# ATSAM3S2B device description
Architecture: CORTEX-M3; Family: SAM3; Series: SAM3S
Registers are 32-bit, read-write, no defined reset value unless marked. A register's access mark holds for its fields unless they carry their own. Offsets are from the block's base; [hi:lo] are bit positions; {n}, {i} and the like mark numbered series.

## CRCCU — Cyclic Redundancy Check Calculation Unit
Instances: CRCCU 0x40044000
0x00 CRCCU_DSCR — CRCCU Descriptor Base Register
  [31:9] DSCR — Descriptor Base Address
0x08 CRCCU_DMA_EN wo — CRCCU DMA Enable Register
  [0] DMAEN — DMA Enable Register
0x0C CRCCU_DMA_DIS wo — CRCCU DMA Disable Register
  [0] DMADIS — DMA Disable Register
0x10 CRCCU_DMA_SR ro — CRCCU DMA Status Register
  [0] DMASR — DMA Status Register
0x14 CRCCU_DMA_IER wo — CRCCU DMA Interrupt Enable Register
  [0] DMAIER — Interrupt Enable register
0x18 CRCCU_DMA_IDR wo — CRCCU DMA Interrupt Disable Register
  [0] DMAIDR — Interrupt Disable register
0x1C CRCCU_DMA_IMR ro — CRCCU DMA Interrupt Mask Register
  [0] DMAIMR — Interrupt Mask Register
0x20 CRCCU_DMA_ISR ro — CRCCU DMA Interrupt Status Register
  [0] DMAISR — Interrupt Status register
0x34 CRCCU_CR wo — CRCCU Control Register
  [0] RESET — CRC Computation Reset
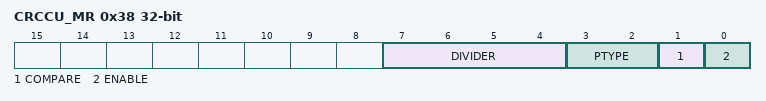
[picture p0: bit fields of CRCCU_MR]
0x38 CRCCU_MR — CRCCU Mode Register
  [7:4] DIVIDER — Request Divider
  [3:2] PTYPE — Primitive Polynomial
    0=CCITT8023 (Polynom 0x04C11DB7); 1=CASTAGNOLI (Polynom 0x1EDC6F41); 2=CCITT16 (Polynom 0x1021)
  [1] COMPARE — CRC Compare
  [0] ENABLE — CRC Enable
0x3C CRCCU_SR ro — CRCCU Status Register
  [31:0] CRC — Cyclic Redundancy Check Value
0x40 CRCCU_IER wo — CRCCU Interrupt Enable Register
  [0] ERRIER — CRC Error Interrupt Enable
0x44 CRCCU_IDR wo — CRCCU Interrupt Disable Register
  [0] ERRIDR — CRC Error Interrupt Disable
0x48 CRCCU_IMR ro — CRCCU Interrupt Mask Register
  [0] ERRIMR — CRC Error Interrupt Mask
0x4C CRCCU_ISR ro — CRCCU Interrupt Status Register
  [0] ERRISR — CRC Error Interrupt Status

## EFC — Embedded Flash Controller
Instances: EFC 0x400E0A00
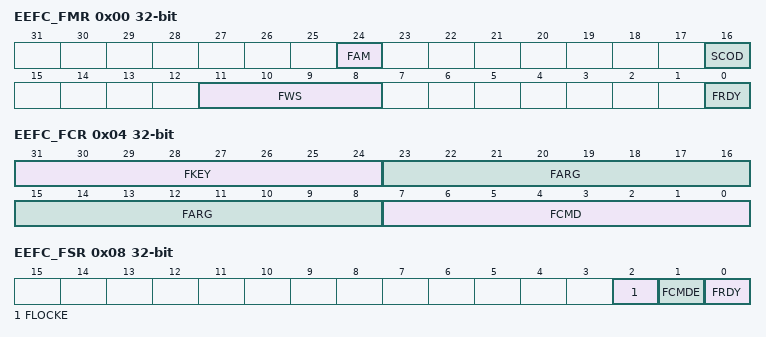
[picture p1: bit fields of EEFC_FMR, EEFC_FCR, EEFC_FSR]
0x00 EEFC_FMR — EEFC Flash Mode Register
  [24] FAM — Flash Access Mode
  [16] SCOD — Sequential Code Optimization Disable
  [11:8] FWS — Flash Wait State
  [0] FRDY — Ready Interrupt Enable
0x04 EEFC_FCR wo — EEFC Flash Command Register
  [31:24] FKEY — Flash Writing Protection Key
    90=PASSWD (The 0x5A value enables the command defined by the bits of the register. If the field is written with a different value, the write is not performed and no action is started.)
  [23:8] FARG — Flash Command Argument
  [7:0] FCMD — Flash Command
    0=GETD (Get Flash Descriptor); 1=WP (Write page); 2=WPL (Write page and lock); 3=EWP (Erase page and write page); 4=EWPL (Erase page and write page then lock); 5=EA (Erase all); 8=SLB (Set Lock Bit); 9=CLB (Clear Lock Bit); 10=GLB (Get Lock Bit); 11=SGPB (Set GPNVM Bit); 12=CGPB (Clear GPNVM Bit); 13=GGPB (Get GPNVM Bit); 14=STUI (Start Read Unique Identifier); 15=SPUI (Stop Read Unique Identifier); 16=GCALB (Get CALIB Bit)
0x08 EEFC_FSR ro — EEFC Flash Status Register
  [2] FLOCKE — Flash Lock Error Status
  [1] FCMDE — Flash Command Error Status
  [0] FRDY — Flash Ready Status
0x0C EEFC_FRR ro — EEFC Flash Result Register
  [31:0] FVALUE — Flash Result Value

## GPBR — General Purpose Backup Registers
Instances: GPBR 0x400E1490
{0x0+4i} SYS_GPBR{i} (i=0..7) — General Purpose Backup Register {i}
  [31:0] GPBR_VALUE — Value of GPBR x

## MATRIX — AHB Bus Matrix
Instances: MATRIX 0x400E0200
{0x0+4i} MATRIX_MCFG{i} (i=0..3) — Master Configuration Register {i}
  [2:0] ULBT — Undefined Length Burst Type
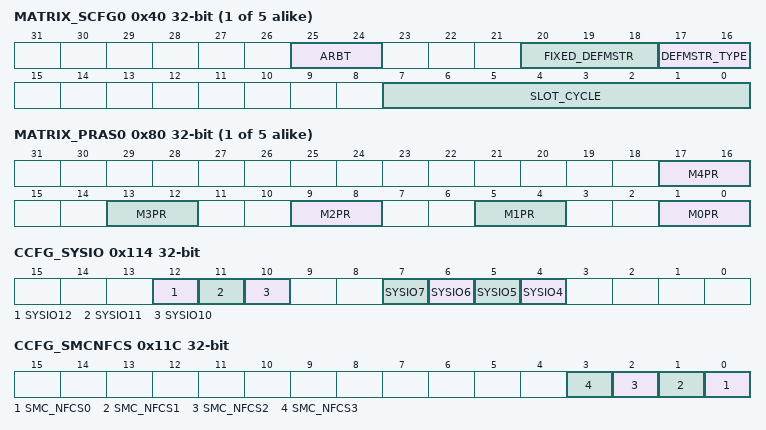
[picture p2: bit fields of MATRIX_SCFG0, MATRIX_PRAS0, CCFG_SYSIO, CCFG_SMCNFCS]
{0x40+4i} MATRIX_SCFG{i} (i=0..4) — Slave Configuration Register {i}
  [25:24] ARBT — Arbitration Type
  [20:18] FIXED_DEFMSTR — Fixed Default Master
  [17:16] DEFMSTR_TYPE — Default Master Type
  [7:0] SLOT_CYCLE — Maximum Number of Allowed Cycles for a Burst
{0x80+8i} MATRIX_PRAS{i} (i=0..4) — Priority Register A for Slave {i}
  [4n+1:4n] M{n}PR (n=0..4) — Master {n} Priority
0x114 CCFG_SYSIO — System I/O Configuration register
  [12] SYSIO12 — PB12 or ERASE Assignment
  [11] SYSIO11 — PB11 or DDP Assignment
  [10] SYSIO10 — PB10 or DDM Assignment
  [7] SYSIO7 — PB7 or TCK/SWCLK Assignment
  [6] SYSIO6 — PB6 or TMS/SWDIO Assignment
  [5] SYSIO5 — PB5 or TDO/TRACESWO Assignment
  [4] SYSIO4 — PB4 or TDI Assignment
0x11C CCFG_SMCNFCS — SMC Chip Select NAND Flash Assignment Register
  [n] SMC_NFCS{n} (n=0..3) — SMC NAND Flash Chip Select {n} Assignment
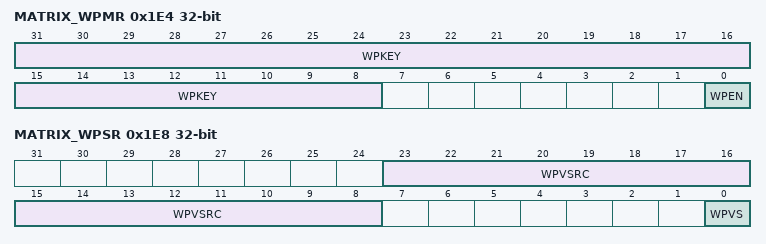
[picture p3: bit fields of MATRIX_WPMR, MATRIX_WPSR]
0x1E4 MATRIX_WPMR — Write Protect Mode Register
  [31:8] WPKEY — Write Protect KEY (Write-only)
  [0] WPEN — Write Protect ENable
0x1E8 MATRIX_WPSR ro — Write Protect Status Register
  [23:8] WPVSRC — Write Protect Violation Source
  [0] WPVS — Write Protect Violation Status

## Notices in the file
SAM Software Package License
Copyright (c) %copyright_year%, Atmel Corporation
All rights reserved.
Redistribution and use in source and binary forms, with or without
modification, are permitted provided that the following condition is met:
- Redistributions of source code must retain the above copyright notice,
this list of conditions and the disclaimer below.
Atmel's name may not be used to endorse or promote products derived from
this software without specific prior written permission.
DISCLAIMER:  THIS SOFTWARE IS PROVIDED BY ATMEL "AS IS" AND ANY EXPRESS OR
IMPLIED WARRANTIES, INCLUDING, BUT NOT LIMITED TO, THE IMPLIED WARRANTIES OF
MERCHANTABILITY, FITNESS FOR A PARTICULAR PURPOSE AND NON-INFRINGEMENT ARE
DISCLAIMED. IN NO EVENT SHALL ATMEL BE LIABLE FOR ANY DIRECT, INDIRECT,
INCIDENTAL, SPECIAL, EXEMPLARY, OR CONSEQUENTIAL DAMAGES (INCLUDING, BUT NOT
LIMITED TO, PROCUREMENT OF SUBSTITUTE GOODS OR SERVICES; LOSS OF USE, DATA,
OR PROFITS; OR BUSINESS INTERRUPTION) HOWEVER CAUSED AND ON ANY THEORY OF
LIABILITY, WHETHER IN CONTRACT, STRICT LIABILITY, OR TORT (INCLUDING
NEGLIGENCE OR OTHERWISE) ARISING IN ANY WAY OUT OF THE USE OF THIS SOFTWARE,
EVEN IF ADVISED OF THE POSSIBILITY OF SUCH DAMAGE.
